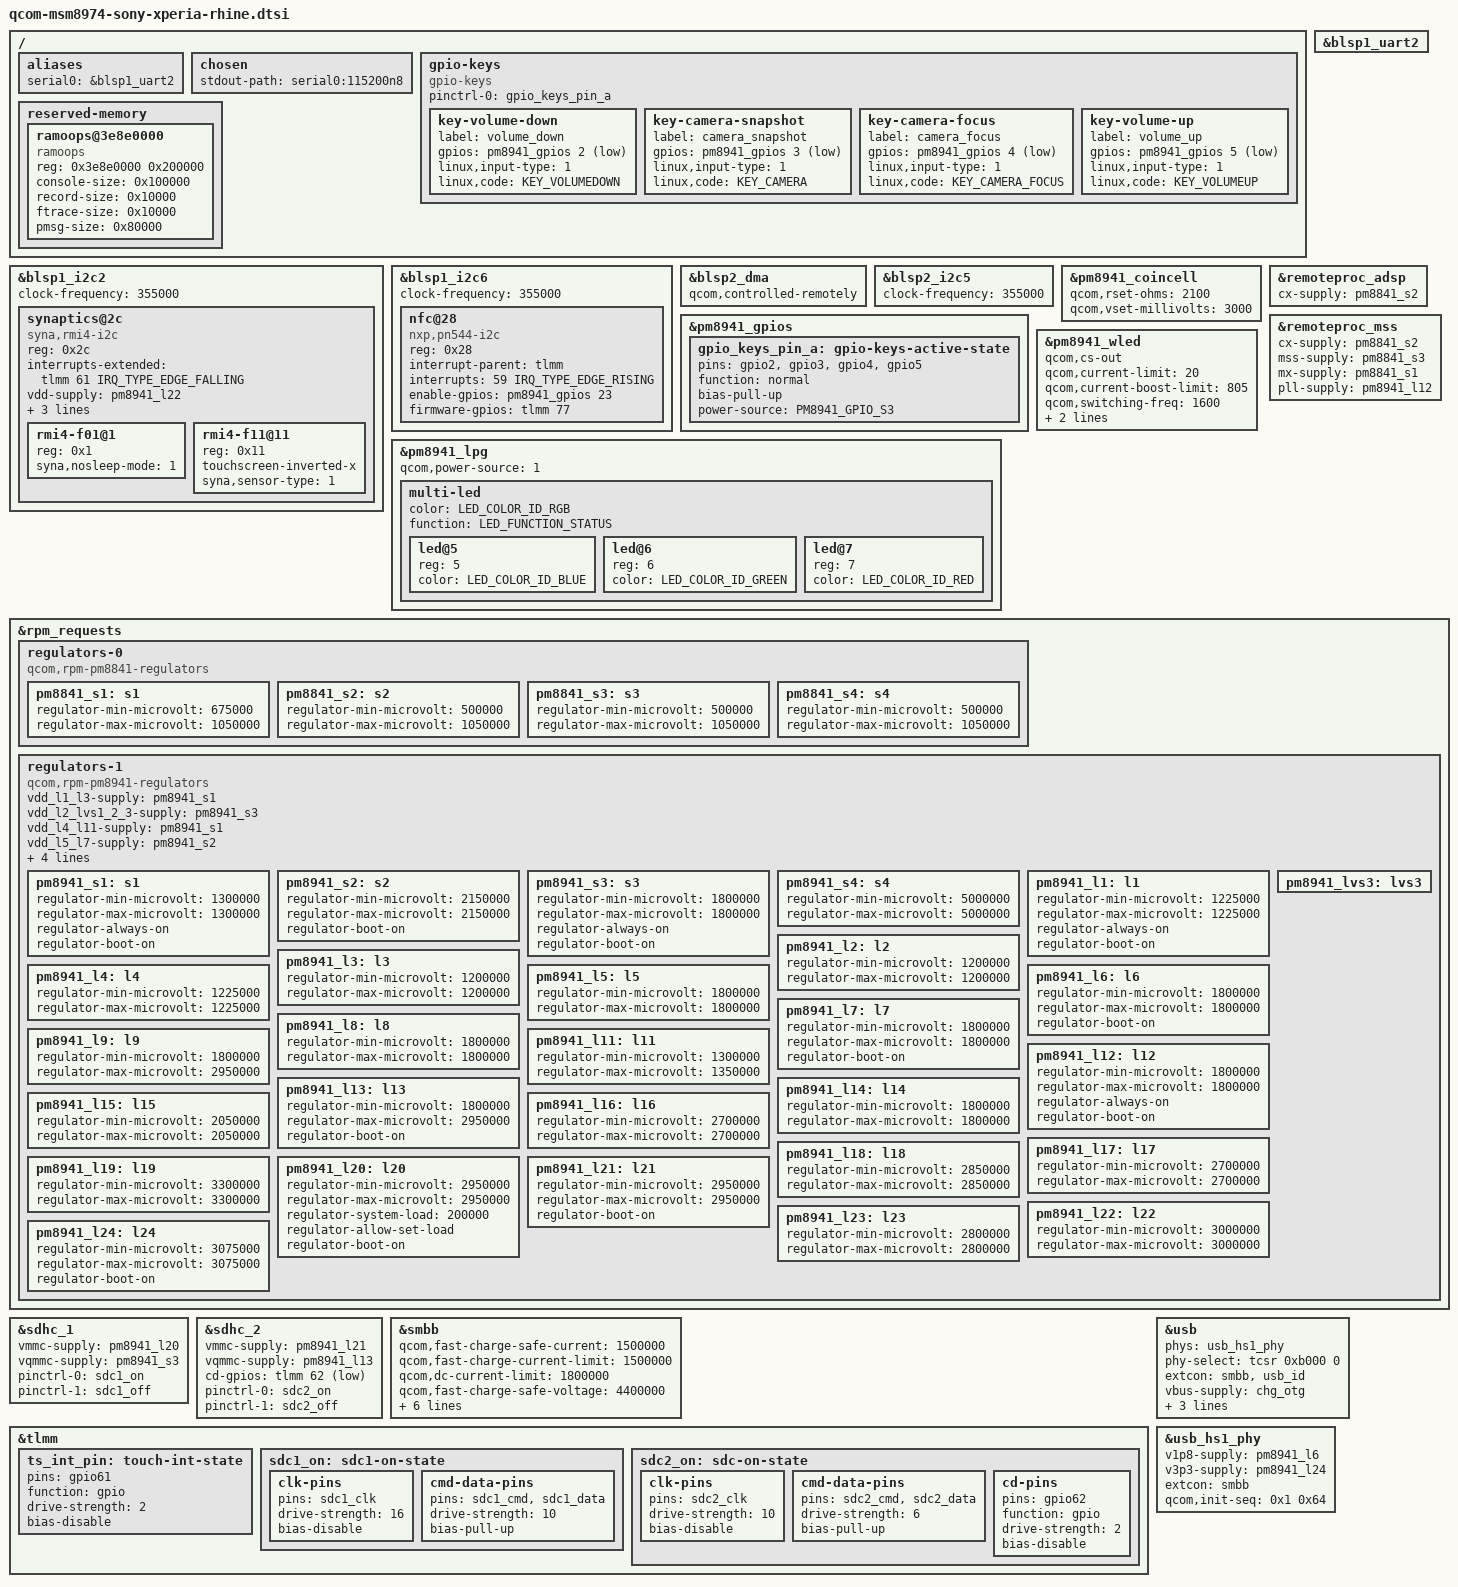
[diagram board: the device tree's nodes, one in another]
// SPDX-License-Identifier: GPL-2.0
#include "qcom-msm8974.dtsi"
#include "pm8841.dtsi"
#include "pm8941.dtsi"
#include <dt-bindings/input/input.h>
#include <dt-bindings/leds/common.h>
#include <dt-bindings/pinctrl/qcom,pmic-gpio.h>

/ {
	aliases {
		serial0 = &blsp1_uart2;
	};

	chosen {
		stdout-path = "serial0:115200n8";
	};

	gpio-keys {
		compatible = "gpio-keys";

		pinctrl-names = "default";
		pinctrl-0 = <&gpio_keys_pin_a>;

		key-volume-down {
			label = "volume_down";
			gpios = <&pm8941_gpios 2 GPIO_ACTIVE_LOW>;
			linux,input-type = <1>;
			linux,code = <KEY_VOLUMEDOWN>;
		};

		key-camera-snapshot {
			label = "camera_snapshot";
			gpios = <&pm8941_gpios 3 GPIO_ACTIVE_LOW>;
			linux,input-type = <1>;
			linux,code = <KEY_CAMERA>;
		};

		key-camera-focus {
			label = "camera_focus";
			gpios = <&pm8941_gpios 4 GPIO_ACTIVE_LOW>;
			linux,input-type = <1>;
			linux,code = <KEY_CAMERA_FOCUS>;
		};

		key-volume-up {
			label = "volume_up";
			gpios = <&pm8941_gpios 5 GPIO_ACTIVE_LOW>;
			linux,input-type = <1>;
			linux,code = <KEY_VOLUMEUP>;
		};
	};

	reserved-memory {
		#address-cells = <1>;
		#size-cells = <1>;
		ranges;

		ramoops@3e8e0000 {
			compatible = "ramoops";
			reg = <0x3e8e0000 0x200000>;

			console-size = <0x100000>;
			record-size = <0x10000>;
			ftrace-size = <0x10000>;
			pmsg-size = <0x80000>;
		};
	};
};

&blsp1_i2c2 {
	status = "okay";
	clock-frequency = <355000>;

	synaptics@2c {
		compatible = "syna,rmi4-i2c";
		reg = <0x2c>;

		interrupts-extended = <&tlmm 61 IRQ_TYPE_EDGE_FALLING>;

		#address-cells = <1>;
		#size-cells = <0>;

		vdd-supply = <&pm8941_l22>;
		vio-supply = <&pm8941_lvs3>;

		pinctrl-names = "default";
		pinctrl-0 = <&ts_int_pin>;

		syna,startup-delay-ms = <10>;

		rmi4-f01@1 {
			reg = <0x1>;
			syna,nosleep-mode = <1>;
		};

		rmi4-f11@11 {
			reg = <0x11>;
			touchscreen-inverted-x;
			syna,sensor-type = <1>;
		};
	};
};

&blsp1_i2c6 {
	status = "okay";
	clock-frequency = <355000>;

	nfc@28 {
		compatible = "nxp,pn544-i2c";
		reg = <0x28>;

		interrupt-parent = <&tlmm>;
		interrupts = <59 IRQ_TYPE_EDGE_RISING>;

		enable-gpios = <&pm8941_gpios 23 GPIO_ACTIVE_HIGH>;
		firmware-gpios = <&tlmm 77 GPIO_ACTIVE_HIGH>;
	};
};

&blsp1_uart2 {
	status = "okay";
};

&blsp2_dma {
	qcom,controlled-remotely;
};

&blsp2_i2c5 {
	status = "okay";
	clock-frequency = <355000>;

	/* sii8334 MHL HDMI bridge */
};

&pm8941_coincell {
	status = "okay";
	qcom,rset-ohms = <2100>;
	qcom,vset-millivolts = <3000>;
};

&pm8941_gpios {
	gpio_keys_pin_a: gpio-keys-active-state {
		pins = "gpio2", "gpio3", "gpio4", "gpio5";
		function = "normal";

		bias-pull-up;
		power-source = <PM8941_GPIO_S3>;
	};
};

&pm8941_lpg {
	status = "okay";

	qcom,power-source = <1>;

	multi-led {
		color = <LED_COLOR_ID_RGB>;
		function = LED_FUNCTION_STATUS;

		#address-cells = <1>;
		#size-cells = <0>;

		led@5 {
			reg = <5>;
			color = <LED_COLOR_ID_BLUE>;
		};

		led@6 {
			reg = <6>;
			color = <LED_COLOR_ID_GREEN>;
		};

		led@7 {
			reg = <7>;
			color = <LED_COLOR_ID_RED>;
		};
	};
};

&pm8941_wled {
	status = "okay";

	qcom,cs-out;
	qcom,current-limit = <20>;
	qcom,current-boost-limit = <805>;
	qcom,switching-freq = <1600>;
	qcom,ovp = <29>;
	qcom,num-strings = <2>;
};

&remoteproc_adsp {
	cx-supply = <&pm8841_s2>;
};

&remoteproc_mss {
	cx-supply = <&pm8841_s2>;
	mss-supply = <&pm8841_s3>;
	mx-supply = <&pm8841_s1>;
	pll-supply = <&pm8941_l12>;
};

&rpm_requests {
	regulators-0 {
		compatible = "qcom,rpm-pm8841-regulators";

		pm8841_s1: s1 {
			regulator-min-microvolt = <675000>;
			regulator-max-microvolt = <1050000>;
		};

		pm8841_s2: s2 {
			regulator-min-microvolt = <500000>;
			regulator-max-microvolt = <1050000>;
		};

		pm8841_s3: s3 {
			regulator-min-microvolt = <500000>;
			regulator-max-microvolt = <1050000>;
		};

		pm8841_s4: s4 {
			regulator-min-microvolt = <500000>;
			regulator-max-microvolt = <1050000>;
		};
	};

	regulators-1 {
		compatible = "qcom,rpm-pm8941-regulators";

		vdd_l1_l3-supply = <&pm8941_s1>;
		vdd_l2_lvs1_2_3-supply = <&pm8941_s3>;
		vdd_l4_l11-supply = <&pm8941_s1>;
		vdd_l5_l7-supply = <&pm8941_s2>;
		vdd_l6_l12_l14_l15-supply = <&pm8941_s2>;
		vdd_l9_l10_l17_l22-supply = <&vreg_boost>;
		vdd_l13_l20_l23_l24-supply = <&vreg_boost>;
		vdd_l21-supply = <&vreg_boost>;

		pm8941_s1: s1 {
			regulator-min-microvolt = <1300000>;
			regulator-max-microvolt = <1300000>;
			regulator-always-on;
			regulator-boot-on;
		};

		pm8941_s2: s2 {
			regulator-min-microvolt = <2150000>;
			regulator-max-microvolt = <2150000>;
			regulator-boot-on;
		};

		pm8941_s3: s3 {
			regulator-min-microvolt = <1800000>;
			regulator-max-microvolt = <1800000>;
			regulator-always-on;
			regulator-boot-on;
		};

		pm8941_s4: s4 {
			regulator-min-microvolt = <5000000>;
			regulator-max-microvolt = <5000000>;
		};

		pm8941_l1: l1 {
			regulator-min-microvolt = <1225000>;
			regulator-max-microvolt = <1225000>;
			regulator-always-on;
			regulator-boot-on;
		};

		pm8941_l2: l2 {
			regulator-min-microvolt = <1200000>;
			regulator-max-microvolt = <1200000>;
		};

		pm8941_l3: l3 {
			regulator-min-microvolt = <1200000>;
			regulator-max-microvolt = <1200000>;
		};

		pm8941_l4: l4 {
			regulator-min-microvolt = <1225000>;
			regulator-max-microvolt = <1225000>;
		};

		pm8941_l5: l5 {
			regulator-min-microvolt = <1800000>;
			regulator-max-microvolt = <1800000>;
		};

		pm8941_l6: l6 {
			regulator-min-microvolt = <1800000>;
			regulator-max-microvolt = <1800000>;
			regulator-boot-on;
		};

		pm8941_l7: l7 {
			regulator-min-microvolt = <1800000>;
			regulator-max-microvolt = <1800000>;
			regulator-boot-on;
		};

		pm8941_l8: l8 {
			regulator-min-microvolt = <1800000>;
			regulator-max-microvolt = <1800000>;
		};

		pm8941_l9: l9 {
			regulator-min-microvolt = <1800000>;
			regulator-max-microvolt = <2950000>;
		};

		pm8941_l11: l11 {
			regulator-min-microvolt = <1300000>;
			regulator-max-microvolt = <1350000>;
		};

		pm8941_l12: l12 {
			regulator-min-microvolt = <1800000>;
			regulator-max-microvolt = <1800000>;
			regulator-always-on;
			regulator-boot-on;
		};

		pm8941_l13: l13 {
			regulator-min-microvolt = <1800000>;
			regulator-max-microvolt = <2950000>;
			regulator-boot-on;
		};

		pm8941_l14: l14 {
			regulator-min-microvolt = <1800000>;
			regulator-max-microvolt = <1800000>;
		};

		pm8941_l15: l15 {
			regulator-min-microvolt = <2050000>;
			regulator-max-microvolt = <2050000>;
		};

		pm8941_l16: l16 {
			regulator-min-microvolt = <2700000>;
			regulator-max-microvolt = <2700000>;
		};

		pm8941_l17: l17 {
			regulator-min-microvolt = <2700000>;
			regulator-max-microvolt = <2700000>;
		};

		pm8941_l18: l18 {
			regulator-min-microvolt = <2850000>;
			regulator-max-microvolt = <2850000>;
		};

		pm8941_l19: l19 {
			regulator-min-microvolt = <3300000>;
			regulator-max-microvolt = <3300000>;
		};

		pm8941_l20: l20 {
			regulator-min-microvolt = <2950000>;
			regulator-max-microvolt = <2950000>;
			regulator-system-load = <200000>;
			regulator-allow-set-load;
			regulator-boot-on;
		};

		pm8941_l21: l21 {
			regulator-min-microvolt = <2950000>;
			regulator-max-microvolt = <2950000>;
			regulator-boot-on;
		};

		pm8941_l22: l22 {
			regulator-min-microvolt = <3000000>;
			regulator-max-microvolt = <3000000>;
		};

		pm8941_l23: l23 {
			regulator-min-microvolt = <2800000>;
			regulator-max-microvolt = <2800000>;
		};

		pm8941_l24: l24 {
			regulator-min-microvolt = <3075000>;
			regulator-max-microvolt = <3075000>;
			regulator-boot-on;
		};

		pm8941_lvs3: lvs3 {};
	};
};

&sdhc_1 {
	status = "okay";

	vmmc-supply = <&pm8941_l20>;
	vqmmc-supply = <&pm8941_s3>;

	pinctrl-names = "default", "sleep";
	pinctrl-0 = <&sdc1_on>;
	pinctrl-1 = <&sdc1_off>;
};

&sdhc_2 {
	status = "okay";

	vmmc-supply = <&pm8941_l21>;
	vqmmc-supply = <&pm8941_l13>;

	cd-gpios = <&tlmm 62 GPIO_ACTIVE_LOW>;

	pinctrl-names = "default", "sleep";
	pinctrl-0 = <&sdc2_on>;
	pinctrl-1 = <&sdc2_off>;
};

&smbb {
	qcom,fast-charge-safe-current = <1500000>;
	qcom,fast-charge-current-limit = <1500000>;
	qcom,dc-current-limit = <1800000>;
	qcom,fast-charge-safe-voltage = <4400000>;
	qcom,fast-charge-high-threshold-voltage = <4350000>;
	qcom,fast-charge-low-threshold-voltage = <3400000>;
	qcom,auto-recharge-threshold-voltage = <4200000>;
	qcom,minimum-input-voltage = <4300000>;
};

&tlmm {
	ts_int_pin: touch-int-state {
		pins = "gpio61";
		function = "gpio";
		drive-strength = <2>;
		bias-disable;
	};

	sdc1_on: sdc1-on-state {
		clk-pins {
			pins = "sdc1_clk";
			drive-strength = <16>;
			bias-disable;
		};

		cmd-data-pins {
			pins = "sdc1_cmd", "sdc1_data";
			drive-strength = <10>;
			bias-pull-up;
		};
	};

	sdc2_on: sdc-on-state {
		clk-pins {
			pins = "sdc2_clk";
			drive-strength = <10>;
			bias-disable;
		};

		cmd-data-pins {
			pins = "sdc2_cmd", "sdc2_data";
			drive-strength = <6>;
			bias-pull-up;
		};

		cd-pins {
			pins = "gpio62";
			function = "gpio";
			drive-strength = <2>;
			bias-disable;
		};
	};
};

&usb {
	status = "okay";

	phys = <&usb_hs1_phy>;
	phy-select = <&tcsr 0xb000 0>;
	extcon = <&smbb>, <&usb_id>;
	vbus-supply = <&chg_otg>;

	hnp-disable;
	srp-disable;
	adp-disable;
};

&usb_hs1_phy {
	status = "okay";

	v1p8-supply = <&pm8941_l6>;
	v3p3-supply = <&pm8941_l24>;

	extcon = <&smbb>;
	qcom,init-seq = /bits/ 8 <0x1 0x64>;
};
